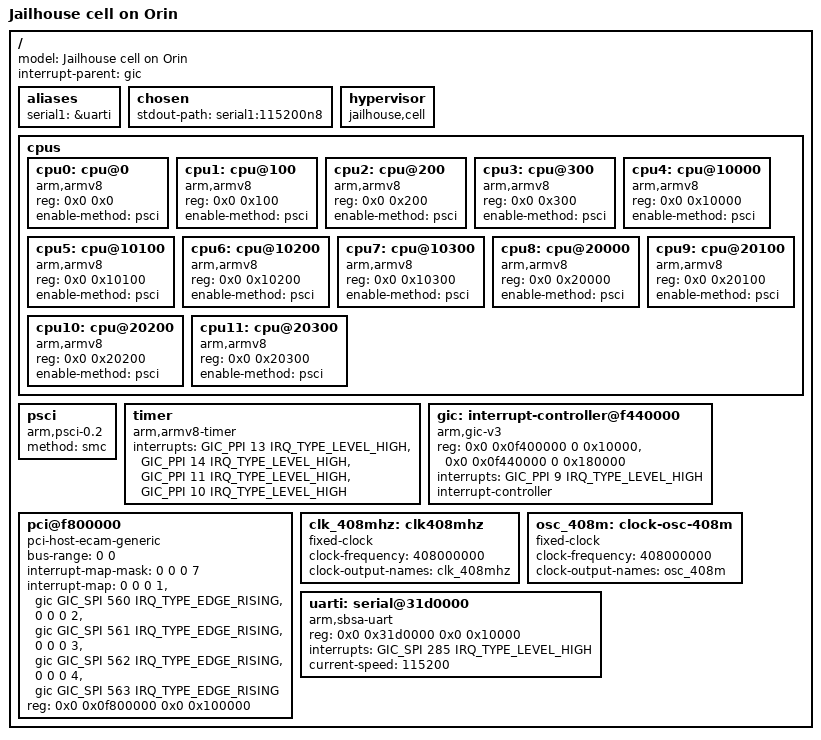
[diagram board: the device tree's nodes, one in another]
/* SPDX-License-Identifier: GPL-2.0 */
/*
 * Jailhouse, a Linux-based partitioning hypervisor
 *
 * Configuration for RK3588 and RK3588S SoCs
 *
 * Copyright (c) 2024 Minerva Systems
 *
 * Authors:
 *  Alex Zuepke <alex.zuepke@minervasys.tech>
 *
 * This work is licensed under the terms of the GNU GPL, version 2.
 * See the COPYING file in the top-level directory.
 *
 * Linux guest cell.
 *
 * We configure the kernel to use all cores that are enabled in the cell config.
 *
 * We'll use UART0 as output, so you have to enable it in the root cell's DTB:
 *   &uart0 {
 *     status = "okay";
 *   };
 *
 * Change here and the root cell DTB accordingly to activate the other serials.
 */

/dts-v1/;

#include <dt-bindings/interrupt-controller/arm-gic.h>

/ {
	model = "Jailhouse cell on Orin";
	interrupt-parent = <&gic>;
	#address-cells = <2>;
	#size-cells = <2>;

	aliases {
		serial1 = &uarti;
	};

	chosen {
		stdout-path = "serial1:115200n8";
	};

	hypervisor {
		compatible = "jailhouse,cell";
	};

	cpus {
		#address-cells = <2>;
		#size-cells = <0>;

		cpu0: cpu@0 {
			device_type = "cpu";
			compatible = "arm,armv8";
			reg = <0x0 0x0>;
			#cooling-cells = <2>;
			enable-method = "psci";
		};

		cpu1: cpu@100 {
			device_type = "cpu";
			compatible = "arm,armv8";
			reg = <0x0 0x100>;
			#cooling-cells = <2>;
			enable-method = "psci";
		};

		cpu2: cpu@200 {
			device_type = "cpu";
			compatible = "arm,armv8";
			reg = <0x0 0x200>;
			#cooling-cells = <2>;
			enable-method = "psci";
		};

		cpu3: cpu@300 {
			device_type = "cpu";
			compatible = "arm,armv8";
			reg = <0x0 0x300>;
			#cooling-cells = <2>;
			enable-method = "psci";
		};

		cpu4: cpu@10000 {
			device_type = "cpu";
			compatible = "arm,armv8";
			reg = <0x0 0x10000>;
			#cooling-cells = <2>;
			enable-method = "psci";
		};

		cpu5: cpu@10100 {
			device_type = "cpu";
			compatible = "arm,armv8";
			reg = <0x0 0x10100>;
			#cooling-cells = <2>;
			enable-method = "psci";
		};

		cpu6: cpu@10200 {
			device_type = "cpu";
			compatible = "arm,armv8";
			reg = <0x0 0x10200>;
			#cooling-cells = <2>;
			enable-method = "psci";
		};

		cpu7: cpu@10300 {
			device_type = "cpu";
			compatible = "arm,armv8";
			reg = <0x0 0x10300>;
			#cooling-cells = <2>;
			enable-method = "psci";
		};

		cpu8: cpu@20000 {
			device_type = "cpu";
			compatible = "arm,armv8";
			reg = <0x0 0x20000>;
			#cooling-cells = <2>;
			enable-method = "psci";
		};

		cpu9: cpu@20100 {
			device_type = "cpu";
			compatible = "arm,armv8";
			reg = <0x0 0x20100>;
			#cooling-cells = <2>;
			enable-method = "psci";
		};

		cpu10: cpu@20200 {
			device_type = "cpu";
			compatible = "arm,armv8";
			reg = <0x0 0x20200>;
			#cooling-cells = <2>;
			enable-method = "psci";
		};

		cpu11: cpu@20300 {
			device_type = "cpu";
			compatible = "arm,armv8";
			reg = <0x0 0x20300>;
			#cooling-cells = <2>;
			enable-method = "psci";
		};
	};

	psci {
		compatible = "arm,psci-0.2";
		method = "smc";
	};

	timer {
		compatible = "arm,armv8-timer";
		interrupts = <GIC_PPI 13 IRQ_TYPE_LEVEL_HIGH>,
			     <GIC_PPI 14 IRQ_TYPE_LEVEL_HIGH>,
			     <GIC_PPI 11 IRQ_TYPE_LEVEL_HIGH>,
			     <GIC_PPI 10 IRQ_TYPE_LEVEL_HIGH>;
	};

	gic: interrupt-controller@f440000 {
		compatible = "arm,gic-v3";
		reg = <0x0 0x0f400000 0 0x10000>, /* GICD */
		      <0x0 0x0f440000 0 0x180000>; /* GICR */
		interrupts = <GIC_PPI 9 IRQ_TYPE_LEVEL_HIGH>;
		interrupt-controller;
		#interrupt-cells = <3>;
	};

	pci@f800000 {
		compatible = "pci-host-ecam-generic";
		device_type = "pci";
		bus-range = <0 0>;
		#address-cells = <3>;
		#size-cells = <2>;
		#interrupt-cells = <1>;
		interrupt-map-mask = <0 0 0 7>;
		interrupt-map = <0 0 0 1 &gic GIC_SPI 560 IRQ_TYPE_EDGE_RISING>,
				<0 0 0 2 &gic GIC_SPI 561 IRQ_TYPE_EDGE_RISING>,
				<0 0 0 3 &gic GIC_SPI 562 IRQ_TYPE_EDGE_RISING>,
				<0 0 0 4 &gic GIC_SPI 563 IRQ_TYPE_EDGE_RISING>;
		reg = <0x0 0x0f800000 0x0 0x100000>;
		ranges =
			<0x02000000 0x00 0x10000000 0x0 0x10000000 0x00 0x10000>;
	};

	clk_408mhz: clk408mhz {
		compatible = "fixed-clock";
		#clock-cells = <0>;
		clock-frequency = <408000000>;
		clock-output-names = "clk_408mhz";
	};

	osc_408m: clock-osc-408m {
		compatible = "fixed-clock";
		#clock-cells = <0>;
		clock-frequency = <408000000>;
		clock-output-names = "osc_408m";
	};

    uarti: serial@31d0000 {
		compatible = "arm,sbsa-uart";
		reg = <0x0 0x31d0000 0x0 0x10000>;
        interrupts = <GIC_SPI 285 IRQ_TYPE_LEVEL_HIGH>;
		current-speed = <115200>;
		status = "okay";
	};
	
};
